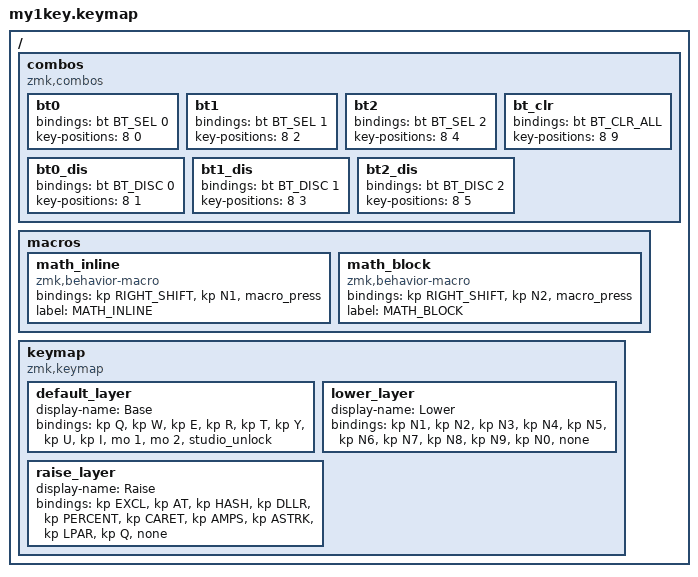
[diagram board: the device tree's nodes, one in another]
#include <behaviors.dtsi>
#include <dt-bindings/zmk/bt.h>
#include <dt-bindings/zmk/keys.h>

/ {
    combos {
        compatible = "zmk,combos";

        bt0 {
            bindings = <&bt BT_SEL 0>;
            key-positions = <8 0>;
        };

        bt1 {
            bindings = <&bt BT_SEL 1>;
            key-positions = <8 2>;
        };

        bt2 {
            bindings = <&bt BT_SEL 2>;
            key-positions = <8 4>;
        };

        bt_clr {
            bindings = <&bt BT_CLR_ALL>;
            key-positions = <8 9>;
        };

        bt0_dis {
            bindings = <&bt BT_DISC 0>;
            key-positions = <8 1>;
        };

        bt1_dis {
            bindings = <&bt BT_DISC 1>;
            key-positions = <8 3>;
        };

        bt2_dis {
            bindings = <&bt BT_DISC 2>;
            key-positions = <8 5>;
        };
    };

    macros {
        math_inline: math_inline {
            compatible = "zmk,behavior-macro";
            #binding-cells = <0>;
            bindings = <&kp RIGHT_SHIFT &kp N1>, <&macro_press>;

            label = "MATH_INLINE";
        };

        math_block: math_block {
            compatible = "zmk,behavior-macro";
            #binding-cells = <0>;
            bindings = <&kp RIGHT_SHIFT &kp N2>, <&macro_press>;

            label = "MATH_BLOCK";
        };
    };

    keymap {
        compatible = "zmk,keymap";

        default_layer {
            display-name = "Base";
            bindings = <
&kp Q
       &kp W
              &kp E
                     &kp R
                            &kp T
                                   &kp Y
                                          &kp U
                                                 &kp I
                                                        &mo 1
                                                               &mo 2
                                                                      &studio_unlock
            >;
        };

        lower_layer {
            display-name = "Lower";
            bindings = <
&kp N1
        &kp N2
                &kp N3
                        &kp N4
                                &kp N5
                                        &kp N6
                                                &kp N7
                                                        &kp N8
                                                                &kp N9
                                                                        &kp N0
                                                                                &none
            >;
        };

        raise_layer {
            display-name = "Raise";
            bindings = <
&kp EXCL
          &kp AT
                  &kp HASH
                            &kp DLLR
                                      &kp PERCENT
                                                   &kp CARET
                                                              &kp AMPS
                                                                        &kp ASTRK
                                                                                   &kp LPAR
                                                                                             &kp Q
                                                                                                    &none
            >;
        };
    };
};
